# M2Sxxx register map
Vendor: Microsemi; Series: SmartFusion2; File version: 2.0.32
CPU: CM3 r2p1, little endian, MPU, no FPU, 4 interrupt priority bits
Registers are 32-bit, read-write, no defined reset value unless marked. A register's access mark holds for its fields unless they carry their own. Offsets are from the block's base; [hi:lo] are bit positions; {n}, {i} and the like mark numbered series.

## GPIO — General-purpose IO peripheral
Base 0x40013000
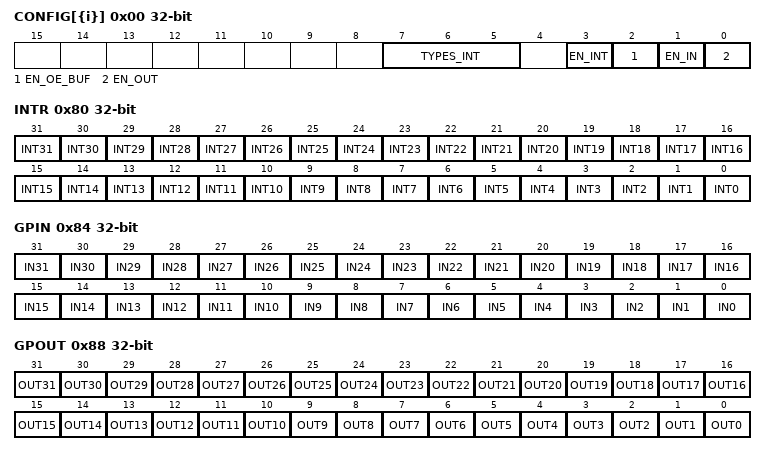
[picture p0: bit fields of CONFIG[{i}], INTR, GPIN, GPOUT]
0x00 CONFIG[{i}] (i=0..31; step ?) — No description provided for this register
  [7:5] TYPES_INT — Interrupt Type
    0=Int_Level_High (Level High); 1=Int_Level_Low (Level Low); 2=Int_Edge_Positive (Edge Positive); 3=Int_Edge_Negative (Edge_Negative); 4=Int_Edge_Both (Edge Both)
  [3] EN_INT — Interrupt Enable
  [2] EN_OE_BUF — Output Buffer Enable
  [1] EN_IN — Input Reg Enable
  [0] EN_OUT — Output Reg Enable
0x80 INTR — GPIO Interrupt register
  [n] INT{n} (n=0..31) — Interrupt from GPIO_{n}
0x84 GPIN — GPIO input register - Read-only for input configured Ports
  [n] IN{n} (n=0..31) — Input from GPIO_{n}
0x88 GPOUT — GPIO Output register - Writeable/Readable for output configured ports. No action required for input configured ports.
  [n] OUT{n} (n=0..31) — Output from GPIO_{n}

## Watchdog — No description provided for this peripheral
Base 0x40005000
0x00 WDOG_VALUE — No description provided for this register
  [31:0] WDOGVALUE ro — No description provided for this field
0x04 WDOG_LOAD — No description provided for this register
  [31:0] WDOGLOAD ro — No description provided for this field
0x08 WDOG_MVRP — No description provided for this register
  [31:0] WDOGMVRP ro — No description provided for this field
0x0C WDOG_REFRESH — No description provided for this register
  [31:0] WDOGREFRESH wo — No description provided for this field
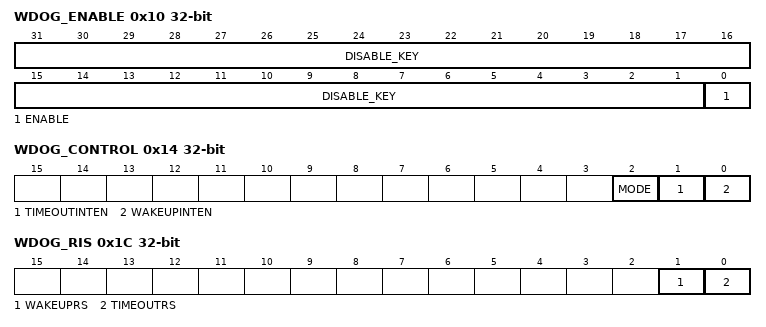
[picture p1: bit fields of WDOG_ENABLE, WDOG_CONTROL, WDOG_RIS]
0x10 WDOG_ENABLE — No description provided for this register
  [31:1] DISABLE_KEY ro — No description provided for this field
  [0] ENABLE ro — No description provided for this field
0x14 WDOG_CONTROL — No description provided for this register
  [2] MODE — No description provided for this field
  [1] TIMEOUTINTEN — No description provided for this field
  [0] WAKEUPINTEN — No description provided for this field
0x18 WDOG_STATUS — No description provided for this register
  [0] REFRESHSTATUS ro — No description provided for this field
0x1C WDOG_RIS — No description provided for this register
  [1] WAKEUPRS — No description provided for this field
  [0] TIMEOUTRS — No description provided for this field

## I2C0 — No description provided for this peripheral
Base 0x40002000
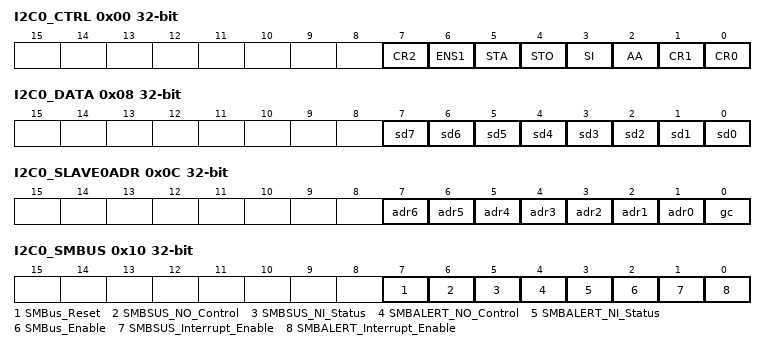
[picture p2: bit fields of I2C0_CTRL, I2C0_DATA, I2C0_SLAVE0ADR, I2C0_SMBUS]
0x00 I2C0_CTRL — No description provided for this register
  [7] CR2 — No description provided for this field
  [6] ENS1 — No description provided for this field
  [5] STA — No description provided for this field
  [4] STO — No description provided for this field
  [3] SI — No description provided for this field
  [2] AA — No description provided for this field
  [1] CR1 — No description provided for this field
  [0] CR0 — No description provided for this field
0x04 I2C0_STATUS — No description provided for this register
  [7:0] Status_Register ro — No description provided for this field
0x08 I2C0_DATA — No description provided for this register
  [n] sd{n} (n=0..7) — No description provided for this field
0x0C I2C0_SLAVE0ADR — No description provided for this register
  [n+1] adr{n} (n=0..6) — No description provided for this field
  [0] gc — No description provided for this field
0x10 I2C0_SMBUS — No description provided for this register
  [7] SMBus_Reset — No description provided for this field
  [6] SMBSUS_NO_Control — No description provided for this field
  [5] SMBSUS_NI_Status — No description provided for this field
  [4] SMBALERT_NO_Control — No description provided for this field
  [3] SMBALERT_NI_Status — No description provided for this field
  [2] SMBus_Enable — No description provided for this field
  [1] SMBSUS_Interrupt_Enable — No description provided for this field
  [0] SMBALERT_Interrupt_Enable — No description provided for this field
0x14 I2C0_FREQ — No description provided for this register
  [7:0] Frequency — No description provided for this field
0x18 I2C0_GLITCHREG — No description provided for this register
  [7:0] GlitchReg_Num — No description provided for this field
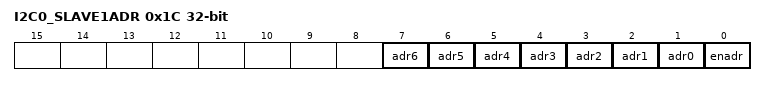
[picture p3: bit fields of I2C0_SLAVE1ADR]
0x1C I2C0_SLAVE1ADR — No description provided for this register
  [n+1] adr{n} (n=0..6) — No description provided for this field
  [0] enadr — No description provided for this field

## I2C1 — No description provided for this peripheral
Base 0x40012000
Registers as I2C0 (with I2C0 read as I2C1).
